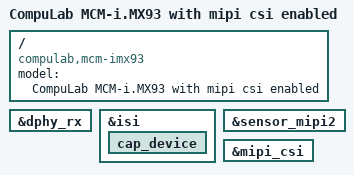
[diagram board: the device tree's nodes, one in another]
// SPDX-License-Identifier: (GPL-2.0+ OR MIT)
/*
 * Copyright 2026 CompuLab Ltd.
 */

/dts-v1/;

#include "mcm-imx93.dtsi"
#include "mcm-imx93-lvds.dtsi"
#include "sbc-mcm-imx93-i2c.dtsi"
#include "mcm-imx93-camera.dtsi"

/ {
	model = "CompuLab MCM-i.MX93 with mipi csi enabled";
	compatible = "compulab,mcm-imx93", "fsl,imx93";
};

&dphy_rx {
	status = "okay";
};

&isi {
	status = "okay";

	cap_device {
		status = "okay";
	};
};

&sensor_mipi2 {
	status = "okay";
};

&mipi_csi {
        status = "okay";
};
